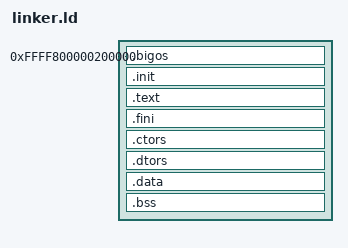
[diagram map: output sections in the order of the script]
OUTPUT_FORMAT("elf64-x86-64", "elf64-x86-64",
	      "elf64-x86-64")
OUTPUT_ARCH(i386:x86-64)
ENTRY(_start)

SEARCH_DIR("C:/Users/forty/Desktop/bigos/lib"); 

SECTIONS
{
  . = 0xffff800000200000;

  .bigos          :
  {
    *(.bigos)
  }
 
  .init           :
  {
    KEEP (*(SORT_NONE(.init)))
  }

  .text           :
  {
    *(.text.unlikely .text.*_unlikely .text.unlikely.*)
    *(.text.exit .text.exit.*)
    *(.text.startup .text.startup.*)
    *(.text.hot .text.hot.*)
    *(SORT(.text.sorted.*))
    *(.text .stub .text.* .gnu.linkonce.t.*)
    /* .gnu.warning sections are handled specially by elf.em.  */
    *(.gnu.warning)
  }

  .fini           :
  {
    KEEP (*(SORT_NONE(.fini)))
  }

  .ctors          :
  {
    /* gcc uses crtbegin.o to find the start of
       the constructors, so we make sure it is
       first.  Because this is a wildcard, it
       doesn't matter if the user does not
       actually link against crtbegin.o; the
       linker won't look for a file to match a
       wildcard.  The wildcard also means that it
       doesn't matter which directory crtbegin.o
       is in.  */
    KEEP (*crtbegin.o(.ctors))
    KEEP (*crtbegin?.o(.ctors))
    /* We don't want to include the .ctor section from
       the crtend.o file until after the sorted ctors.
       The .ctor section from the crtend file contains the
       end of ctors marker and it must be last */
    KEEP (*(EXCLUDE_FILE (*crtend.o *crtend?.o ) .ctors))
    KEEP (*(SORT(.ctors.*)))
    KEEP (*(.ctors))
  }

  .dtors          :
  {
    KEEP (*crtbegin.o(.dtors))
    KEEP (*crtbegin?.o(.dtors))
    KEEP (*(EXCLUDE_FILE (*crtend.o *crtend?.o ) .dtors))
    KEEP (*(SORT(.dtors.*)))
    KEEP (*(.dtors))
  }

  .data           :
  {
    *(.data .data.* .gnu.linkonce.d.*)
    SORT(CONSTRUCTORS)
  }

  .bss            :
  {
   *(.dynbss)
   *(.bss .bss.* .gnu.linkonce.b.*)
   *(COMMON)
   . = ALIGN(. != 0 ? 64 / 8 : 1);
  }

     /DISCARD/ :
   {
        *(.comment)
   }
}
